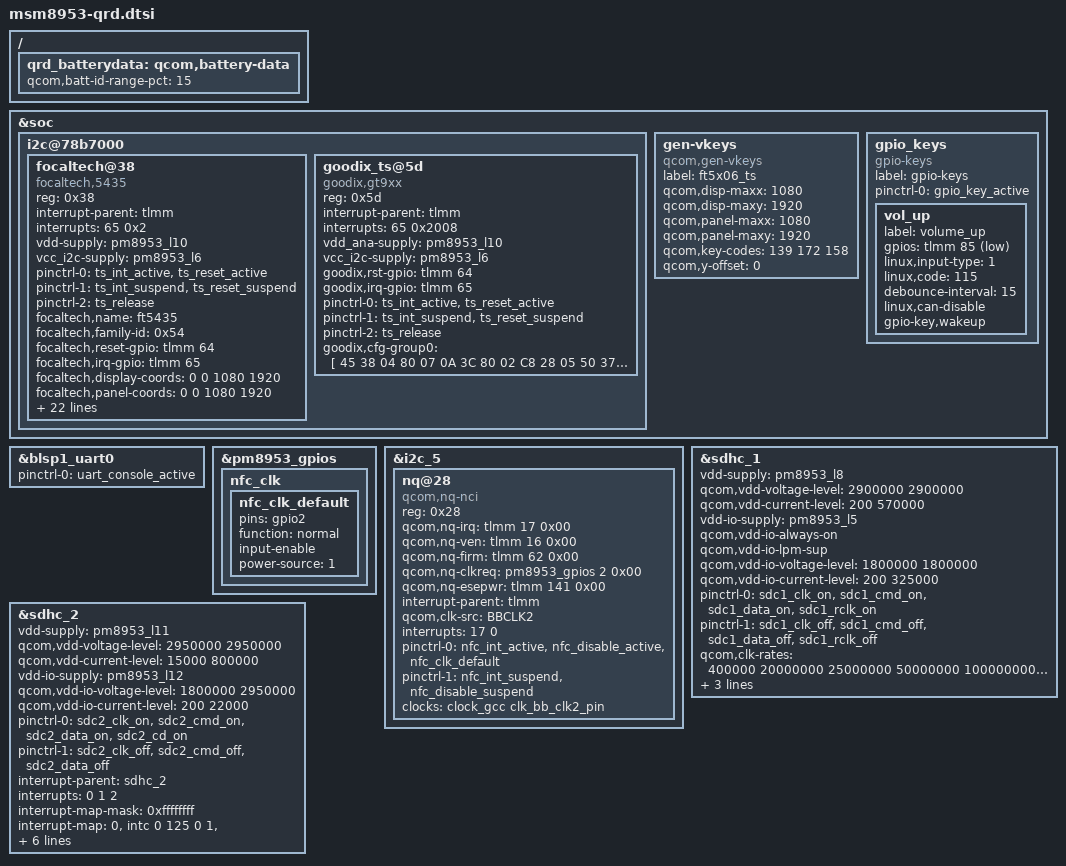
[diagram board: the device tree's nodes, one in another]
/*
 * Copyright (c) 2015-2019, The Linux Foundation. All rights reserved.
 *
 * This program is free software; you can redistribute it and/or modify
 * it under the terms of the GNU General Public License version 2 and
 * only version 2 as published by the Free Software Foundation.
 *
 * This program is distributed in the hope that it will be useful,
 * but WITHOUT ANY WARRANTY; without even the implied warranty of
 * MERCHANTABILITY or FITNESS FOR A PARTICULAR PURPOSE.  See the
 * GNU General Public License for more details.
 */

#include <dt-bindings/gpio/gpio.h>
#include <dt-bindings/clock/msm-clocks-8953.h>

&soc {
	i2c@78b7000 { /* BLSP1 QUP3 */
		status = "okay";
		focaltech@38 {
                        compatible = "focaltech,5435";
			reg = <0x38>;
			interrupt-parent = <&tlmm>;
			interrupts = <65 0x2>;
			vdd-supply = <&pm8953_l10>;
			vcc_i2c-supply = <&pm8953_l6>;
			/* pins used by touchscreen */
			pinctrl-names = "pmx_ts_active",
						"pmx_ts_suspend",
						"pmx_ts_release";
			pinctrl-0 = <&ts_int_active &ts_reset_active>;
			pinctrl-1 = <&ts_int_suspend &ts_reset_suspend>;
			pinctrl-2 = <&ts_release>;
			focaltech,name = "ft5435";
			focaltech,family-id = <0x54>;
			focaltech,reset-gpio = <&tlmm 64 0x0>;
			focaltech,irq-gpio = <&tlmm 65 0x2008>;
			focaltech,display-coords = <0 0 1080 1920>;
			focaltech,panel-coords = <0 0 1080 1920>;
			focaltech,button-map= <139 172 158>;
			focaltech,no-force-update;
			focaltech,i2c-pull-up;
			focaltech,group-id = <1>;
			focaltech,hard-reset-delay-ms = <200>;
			focaltech,soft-reset-delay-ms = <200>;
			focaltech,num-max-touches = <10>;
			focaltech,fw-delay-aa-ms = <2>;
			focaltech,fw-delay-55-ms = <2>;
			focaltech,fw-upgrade-id1 = <0x54>;
			focaltech,fw-upgrade-id2 = <0x2c>;
			focaltech,fw-delay-readid-ms = <10>;
			focaltech,fw-delay-era-flsh-ms = <2000>;
			focaltech,fw-auto-cal;
			focaltech,fw-vkey-support;
			focaltech,resume-in-workqueue;
			focaltech,num-virtual-key = <3>;
			focal,virtual_key_1 = <172 500 2040>;/*home*/
			focal,virtual_key_2 = <139 200 2040>;/*menu*/
			focal,virtual_key_3 = <158 800 2040>;/*back*/
			/* Underlying clocks used by secure touch */
			clock-names = "iface_clk", "core_clk";
			clocks = <&clock_gcc clk_gcc_blsp1_ahb_clk>,
				<&clock_gcc clk_gcc_blsp1_qup3_i2c_apps_clk>;
		};

             goodix_ts@5d {
			compatible = "goodix,gt9xx";
			reg = <0x5d>;
			interrupt-parent = <&tlmm>;
			interrupts = <65 0x2008>;
			vdd_ana-supply = <&pm8953_l10>;
			vcc_i2c-supply = <&pm8953_l6>;
			goodix,rst-gpio = <&tlmm 64 0x00>;
			goodix,irq-gpio = <&tlmm 65 0x00>;
			pinctrl-names = "pmx_ts_active",
						"pmx_ts_suspend",
						"pmx_ts_release";
			pinctrl-0 = <&ts_int_active &ts_reset_active>;
			pinctrl-1 = <&ts_int_suspend &ts_reset_suspend>;
			pinctrl-2 = <&ts_release>;
			goodix,cfg-group0 = [
                        45 38 04 80 07 0A 3C 80 02 C8 28 
                        05 50 37 03 05 00 00 00 00 11 11 
                        05 16 19 1E 14 87 27 CC 56 58 D3 
                        07 00 00 02 D2 02 11 00 00 00 00 
                        00 03 40 14 14 00 00 3C 64 8F D0 
                        52 08 19 00 04 9F 3F 00 93 46 00 
                        89 4D 00 89 55 00 78 5F 00 78 00 
                        00 00 00 00 00 00 00 00 00 00 00 
                        00 00 00 00 00 00 00 00 00 00 00 
                        00 00 00 00 00 00 00 00 00 00 00 
                        00 00 01 02 03 04 05 06 07 08 0B 
                        0A 09 00 17 16 15 14 13 12 11 10 
                        0F 0E 0D 0C FF FF FF FF FF FF 1E 
                        1F 20 22 24 28 29 0A 08 06 05 04 
                        02 00 FF FF FF 00 00 00 00 00 00 
                        00 00 00 23 32 41 00 00 00 00 00 
                        00 00 00 00 00 5A 00 00 00 00 00 
                        00 00 00 28 5A 00 00 00 00 00 00 
                        00 00 00 00 00 00 00 00 00 00 00 
                        00 00 00 00 00 00 00 00 00 00 00 
                        00 00 00 00 00 00 0C 01];
		};
	 };

	gen-vkeys {
		compatible = "qcom,gen-vkeys";
		label = "ft5x06_ts";
		qcom,disp-maxx = <1080>;
		qcom,disp-maxy = <1920>;
		qcom,panel-maxx = <1080>;
		qcom,panel-maxy = <1920>;
		qcom,key-codes = <139 172 158>;
		qcom,y-offset = <0>;
	};

	gpio_keys {
		compatible = "gpio-keys";
		label = "gpio-keys";
		pinctrl-names = "default";
		pinctrl-0 = <&gpio_key_active>;

		vol_up {
			label = "volume_up";
			gpios = <&tlmm 85 0x1>;
			linux,input-type = <1>;
			linux,code = <115>;
			debounce-interval = <15>;
			linux,can-disable;
			gpio-key,wakeup;
		};
	};
};

/ {
	qrd_batterydata: qcom,battery-data {
		qcom,batt-id-range-pct = <15>;
		#include "batterydata_Amazon_4V4_4000mAh.dtsi"
	};
};

&blsp1_uart0 {
	status = "ok";
	pinctrl-names = "default";
	pinctrl-0 = <&uart_console_active>;
};

&pm8953_gpios {
	nfc_clk {
		nfc_clk_default: nfc_clk_default {
			pins = "gpio2";
			function = "normal";
			input-enable;
			power-source = <1>;
		};
	};
};

&i2c_5 { /* BLSP2 QUP1 (NFC) */
	#address-cells = <1>;
	#size-cells = <0>;

	status = "ok";
	nq@28 {
		compatible = "qcom,nq-nci";
		reg = <0x28>;
		qcom,nq-irq = <&tlmm 17 0x00>;
		qcom,nq-ven = <&tlmm 16 0x00>;
		qcom,nq-firm = <&tlmm 62 0x00>;
		qcom,nq-clkreq = <&pm8953_gpios 2 0x00>;
		qcom,nq-esepwr = <&tlmm 141 0x00>;
		interrupt-parent = <&tlmm>;
		qcom,clk-src = "BBCLK2";
		interrupts = <17 0>;
		interrupt-names = "nfc_irq";
		pinctrl-names = "nfc_active", "nfc_suspend";
		pinctrl-0 = <&nfc_int_active &nfc_disable_active
						&nfc_clk_default>;
		pinctrl-1 = <&nfc_int_suspend &nfc_disable_suspend>;
		clocks = <&clock_gcc clk_bb_clk2_pin>;
		clock-names = "ref_clk";
	};
};

&sdhc_1 {
	/* device core power supply */
	vdd-supply = <&pm8953_l8>;
	qcom,vdd-voltage-level = <2900000 2900000>;
	qcom,vdd-current-level = <200 570000>;

	/* device communication power supply */
	vdd-io-supply = <&pm8953_l5>;
	qcom,vdd-io-always-on;
	qcom,vdd-io-lpm-sup;
	qcom,vdd-io-voltage-level = <1800000 1800000>;
	qcom,vdd-io-current-level = <200 325000>;

	pinctrl-names = "active", "sleep";
	pinctrl-0 = <&sdc1_clk_on &sdc1_cmd_on &sdc1_data_on  &sdc1_rclk_on>;
	pinctrl-1 = <&sdc1_clk_off &sdc1_cmd_off &sdc1_data_off &sdc1_rclk_off>;

	qcom,clk-rates = <400000 20000000 25000000 50000000 100000000 192000000
								384000000>;
	qcom,nonremovable;
	qcom,bus-speed-mode = "HS400_1p8v", "HS200_1p8v", "DDR_1p8v";

	status = "ok";
};

&sdhc_2 {
	/* device core power supply */
	vdd-supply = <&pm8953_l11>;
	qcom,vdd-voltage-level = <2950000 2950000>;
	qcom,vdd-current-level = <15000 800000>;

	/* device communication power supply */
	vdd-io-supply = <&pm8953_l12>;
	qcom,vdd-io-voltage-level = <1800000 2950000>;
	qcom,vdd-io-current-level = <200 22000>;

	pinctrl-names = "active", "sleep";
	pinctrl-0 = <&sdc2_clk_on &sdc2_cmd_on &sdc2_data_on &sdc2_cd_on>;
	pinctrl-1 = <&sdc2_clk_off &sdc2_cmd_off &sdc2_data_off>;

	#address-cells = <0>;
	interrupt-parent = <&sdhc_2>;
	interrupts = <0 1 2>;
	#interrupt-cells = <1>;
	interrupt-map-mask = <0xffffffff>;
	interrupt-map = <0 &intc 0 125 0
		1 &intc 0 221 0
		2 &tlmm 133 0>;
	interrupt-names = "hc_irq", "pwr_irq", "status_irq";
	cd-gpios = <&tlmm 133 0x0>;

	qcom,clk-rates = <400000 20000000 25000000 50000000 100000000
								200000000>;
	qcom,bus-speed-mode = "SDR12", "SDR25", "SDR50", "DDR50", "SDR104";

	status = "ok";
};
